AUTOSAR XML (schema 4-0-3)
standard types defined: UInt32, UInt8
package /AUTOSAR_Platform/DataConstrs
  range DC_UInt8: raw 0..255
package /PATAC/MSM/ComponentTypes
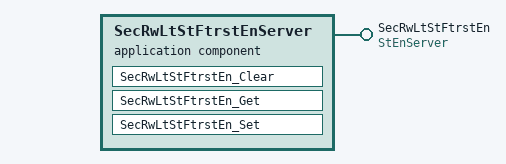
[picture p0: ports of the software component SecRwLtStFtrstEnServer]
  application sw component type SecRwLtStFtrstEnServer
    provide port SecRwLtStFtrstEn: provided-com-specs=[{operation=Clear, queue-length=1}, {operation=Get, queue-length=1}, {operation=Set, queue-length=1}], provided-interface=StEnServer
    behavior SecRwLtStFtrstEnServer_InternalBehavior
      operation invoked event OIT_SecRwLtStFtrstEn_Clear_SecRwLtStFtrstEn_Clear: start-on-event=SecRwLtStFtrstEn_Clear, operation=SecRwLtStFtrstEn.Clear
      operation invoked event OIT_SecRwLtStFtrstEn_Get_SecRwLtStFtrstEn_Get: start-on-event=SecRwLtStFtrstEn_Get, operation=SecRwLtStFtrstEn.Get
      operation invoked event OIT_SecRwLtStFtrstEn_Set_SecRwLtStFtrstEn_Set: start-on-event=SecRwLtStFtrstEn_Set, operation=SecRwLtStFtrstEn.Set
      runnable SecRwLtStFtrstEn_Clear
      runnable SecRwLtStFtrstEn_Get
      runnable SecRwLtStFtrstEn_Set
  swc implementation SecRwLtStFtrstEnServer_Implementation: behavior=SecRwLtStFtrstEnServer_InternalBehavior
    code-descriptors:
      code Default: artifact-descriptors=autosar-engineering-object={short-label=Default, category=SWSRC}
package /PATAC/MSM/ModeAdjust/PortInterface
  client server interface StEnServer
    operation Clear
      arg data: type=UInt8, direction=IN, server-argument-impl-policy=USE-ARGUMENT-TYPE
    operation Get
      arg data: type=UInt32, direction=OUT, server-argument-impl-policy=USE-ARGUMENT-TYPE
    operation Set
      arg data: type=UInt8, direction=IN, server-argument-impl-policy=USE-ARGUMENT-TYPE
